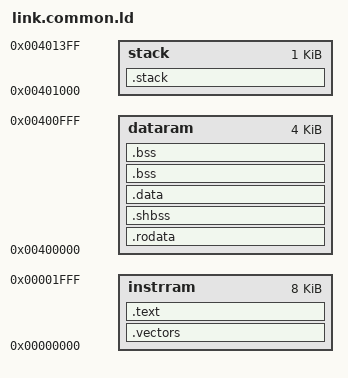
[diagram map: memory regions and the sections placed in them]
SEARCH_DIR(.)
__DYNAMIC  =  0;

MEMORY
{
    instrram    : ORIGIN = 0x00000000, LENGTH = 0x2000
    dataram     : ORIGIN = 0x00400000, LENGTH = 0x1000
    stack       : ORIGIN = 0x00401000, LENGTH = 0x0400
}

/* Stack information variables */
_min_stack      = 0x0400;   /* 4K - minimum stack space to reserve */
_stack_len     = LENGTH(stack);
_stack_start   = ORIGIN(stack) + LENGTH(stack);

/* We have to align each sector to word boundaries as our current s19->slm
 * conversion scripts are not able to handle non-word aligned sections. */

SECTIONS
{
    .vectors :
    {
        . = ALIGN(4);
        KEEP(*(.vectors))
    } > instrram

    .text : {
        . = ALIGN(4);
        _stext = .;
        *(.text)
        _etext  =  .;
        *(.lit)
        *(.shdata)
        _endtext = .;
    }  > instrram

    /*--------------------------------------------------------------------*/
    /* Global constructor/destructor segement                             */
    /*--------------------------------------------------------------------*/

    

    .rodata : {
        . = ALIGN(4);
        *(.rodata);
        *(.rodata.*)
        . = ALIGN(4);
    } > dataram

    .shbss :
    {
        . = ALIGN(4);
        *(.shbss)
        . = ALIGN(4);
    } > dataram

    .data : {
        . = ALIGN(4);
        sdata  =  .;
        _sdata  =  .;
        *(.data);
        *(.data.*)
        . = ALIGN(4);
        edata  =  .;
        _edata  =  .;
    } > dataram

    .bss :
    {
        . = ALIGN(4);
        _bss_start = .;
        *(.bss)
        *(.bss.*)
        *(.sbss)
        *(.sbss.*)
        *(COMMON)
        . = ALIGN(4);
        _bss_end = .;
    } > dataram

    /* ensure there is enough room for stack */
    .stack (NOLOAD): {
        . = ALIGN(4);
        . = . + _min_stack ;
        . = ALIGN(4);
        stack = . ;
        _stack = . ;
    } > stack

    .stab  0 (NOLOAD) :
    {
        [ .stab ]
    }

    .stabstr  0 (NOLOAD) :
    {
        [ .stabstr ]
    }

    .bss :
    {
        . = ALIGN(4);
        _end = .;
    } > dataram
}

